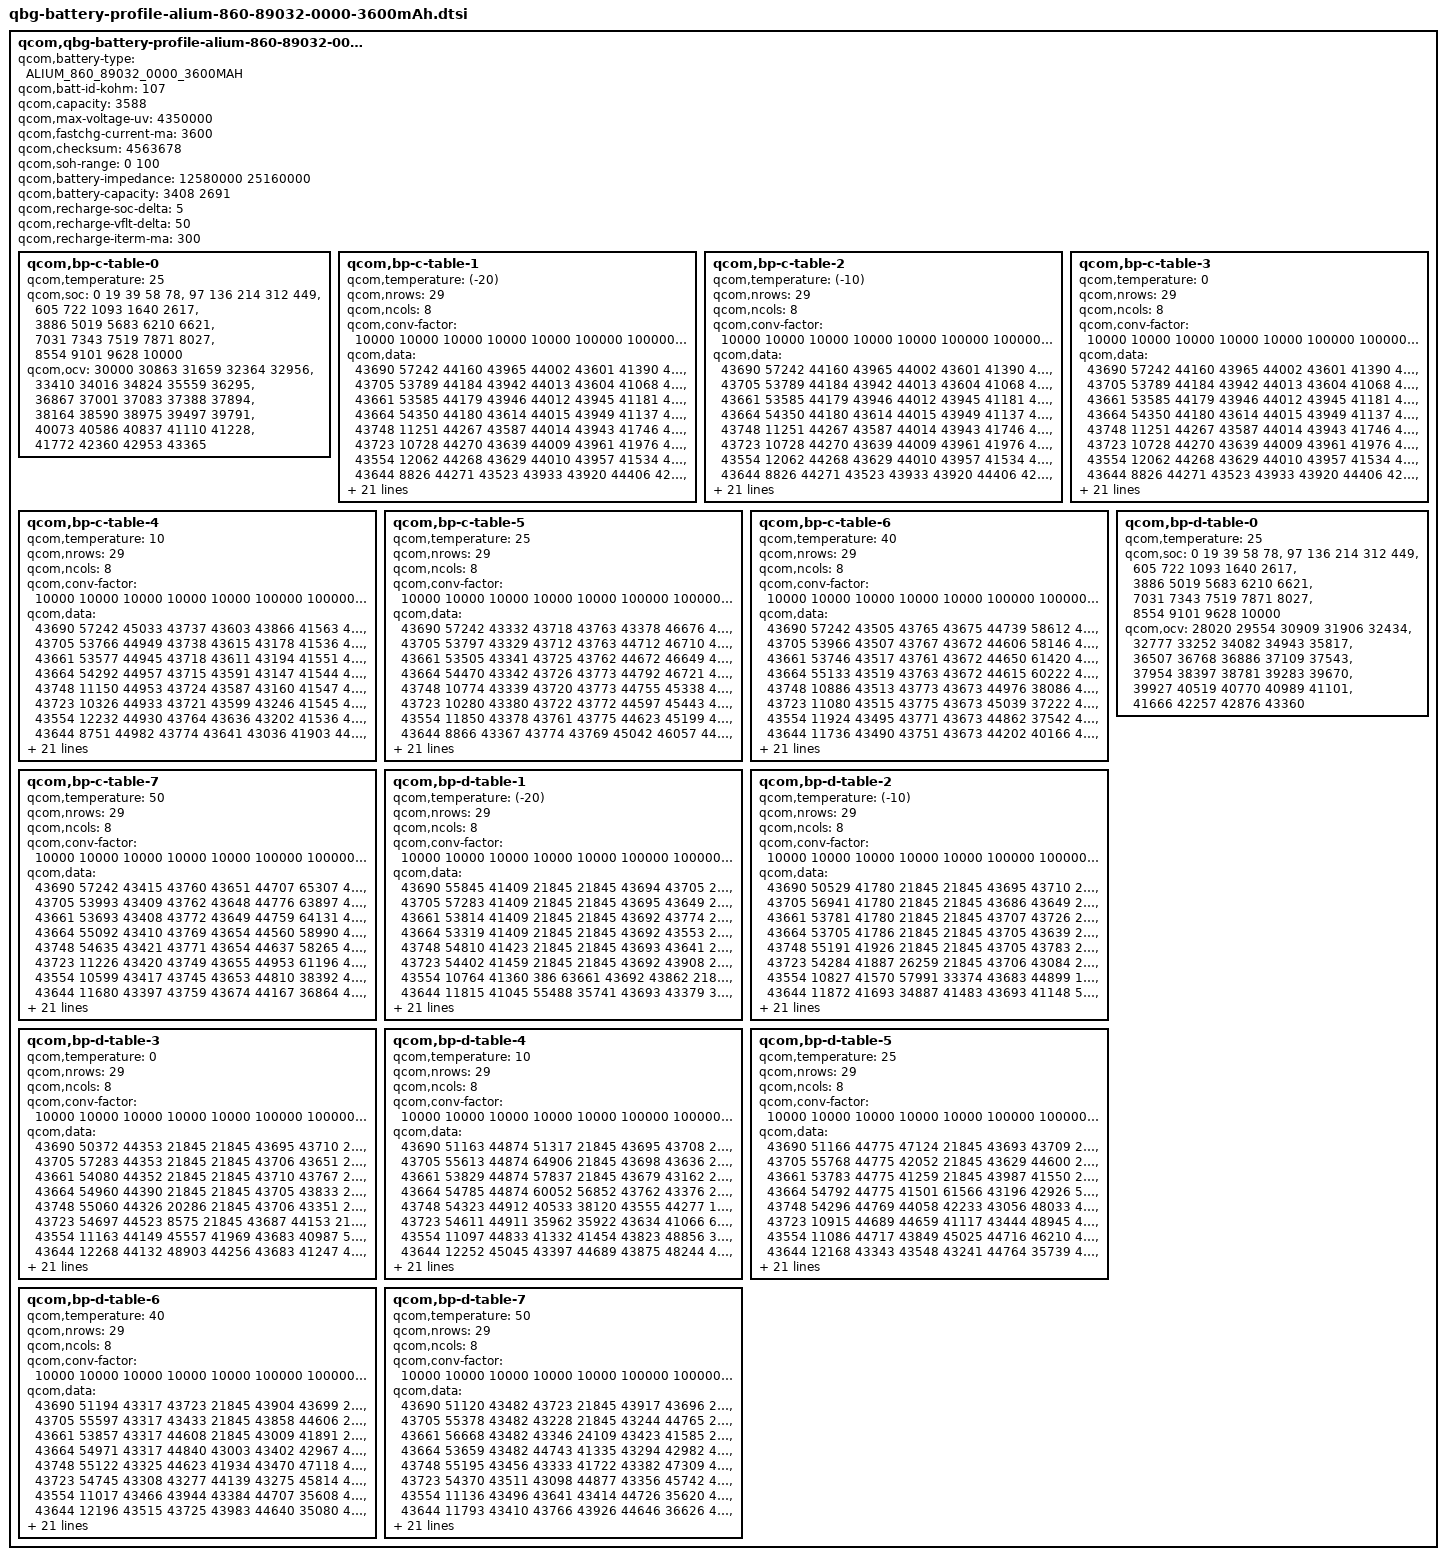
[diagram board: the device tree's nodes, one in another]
qcom,qbg-battery-profile-alium-860-89032-0000-3600mAh {
	qcom,battery-type = "ALIUM_860_89032_0000_3600MAH";
	qcom,batt-id-kohm = <107>;
	qcom,capacity = <3588>;
	qcom,max-voltage-uv = <4350000>;
	qcom,fastchg-current-ma = <3600>;
	qcom,checksum = <4563678>; /*@5, 0.005V, 10% */
	qcom,soh-range = <0 100>;
	qcom,battery-impedance = <12580000 25160000>; /* Nominal_Impedance in 10nohm @ SOC 50% 25C* 0:fresh cell, 1: aged cell */
	qcom,battery-capacity = <3408 2691>; /* Nominal_Capacity in mAh. 0: fresh cell, 1:aged cell */
	qcom,recharge-soc-delta =<5>; /* SOC delta (in percent) dropped from EOC SOC to enable recharge */
	qcom,recharge-vflt-delta =<50>; /* vfloat delta (in mV) dropped from regular vfloat in recharge */
	qcom,recharge-iterm-ma = <300>; /* termination current (in mA) in recharge */

	qcom,bp-c-table-0 {
		qcom,temperature = <25>;
		qcom,soc = <    0    19    39    58    78>,
			<   97   136   214   312   449>,
			<  605   722  1093  1640  2617>,
			< 3886  5019  5683  6210  6621>,
			< 7031  7343  7519  7871  8027>,
			< 8554  9101  9628 10000>;
		qcom,ocv = <30000 30863 31659 32364 32956>,
			<33410 34016 34824 35559 36295>,
			<36867 37001 37083 37388 37894>,
			<38164 38590 38975 39497 39791>,
			<40073 40586 40837 41110 41228>,
			<41772 42360 42953 43365>;
	};

	qcom,bp-c-table-1 {
		qcom,temperature = <(-20)>;
		qcom,nrows = <29>;
		qcom,ncols = <8>;
		qcom,conv-factor = <10000 10000 10000 10000 10000 100000 100000 10000>;
		qcom,data = <43690 57242 44160 43965 44002 43601 41390 42954>,
			<43705 53789 44184 43942 44013 43604 41068 42903>,
			<43661 53585 44179 43946 44012 43945 41181 42931>,
			<43664 54350 44180 43614 44015 43949 41137 42589>,
			<43748 11251 44267 43587 44014 43943 41746 42623>,
			<43723 10728 44270 43639 44009 43961 41976 42526>,
			<43554 12062 44268 43629 44010 43957 41534 42717>,
			<43644  8826 44271 43523 43933 43920 44406 42687>,
			<43922  8449 44185 43570 43907 43976 41611 41327>,
			<43883  9254 44179 43730 43919 43808 44367 41425>,
			<43255 14867 44167 43672 44001 44025 45053 41445>,
			<43128 15244 44168 43672 44029 44024 45048 41451>,
			<44783 15158 44173 43774 44013 43988 44048 41467>,
			<44226 14421 44161 43540 44013 43793 41113 41326>,
			<41107 15967 44173 43625 43776 43793 41789 41295>,
			<42372 15526 44884 43584 43856 43898 41322 41282>,
			<47409 15831 44867 43908 43900 43066 47981 41317>,
			<48281 12906 44874 44012 43875 43131 48704 41247>,
			<45800 13155 44916 43995 43899 43076 48598 41287>,
			<45943 12500 44865 43789 43856 43091 45767 42694>,
			<45533 12745 44884 43866 43224 43448 45801 42993>,
			<46597 13859 44193 43189 43133 43499 45732 42112>,
			<47093 14086 44221 43184 43128 43496 48592 42215>,
			<46101  2729 44165 43176 43029 43392 48814 42199>,
			<46577  2616 44188 43179 43085 43392 47122 42001>,
			<35776  2202 44260 43180 43334 43496 42250 42316>,
			<35111  3788 44259 43191 44671 43496 42897 48054>,
			<36662  3128 44267 43146 44800 43421 41436 47272>,
			<36282   748 44268 43594 44960 41594 44901 47858>;
	};

	qcom,bp-c-table-2 {
		qcom,temperature = <(-10)>;
		qcom,nrows = <29>;
		qcom,ncols = <8>;
		qcom,conv-factor = <10000 10000 10000 10000 10000 100000 100000 10000>;
		qcom,data = <43690 57242 44160 43965 44002 43601 41390 42954>,
			<43705 53789 44184 43942 44013 43604 41068 42903>,
			<43661 53585 44179 43946 44012 43945 41181 42931>,
			<43664 54350 44180 43614 44015 43949 41137 42589>,
			<43748 11251 44267 43587 44014 43943 41746 42623>,
			<43723 10728 44270 43639 44009 43961 41976 42526>,
			<43554 12062 44268 43629 44010 43957 41534 42717>,
			<43644  8826 44271 43523 43933 43920 44406 42687>,
			<43922  8449 44185 43570 43907 43976 41611 41327>,
			<43883  9254 44179 43730 43919 43808 44367 41425>,
			<43255 14867 44167 43672 44001 44025 45053 41445>,
			<43128 15244 44168 43672 44029 44024 45048 41451>,
			<44783 15158 44173 43774 44013 43988 44048 41467>,
			<44226 14421 44161 43540 44013 43793 41113 41326>,
			<41107 15967 44173 43625 43776 43793 41789 41295>,
			<42372 15526 44884 43584 43856 43898 41322 41282>,
			<47409 15831 44867 43908 43900 43066 47981 41317>,
			<48281 12906 44874 44012 43875 43131 48704 41247>,
			<45800 13155 44916 43995 43899 43076 48598 41287>,
			<45943 12500 44865 43789 43856 43091 45767 42694>,
			<45533 12745 44884 43866 43224 43448 45801 42993>,
			<46597 13859 44193 43189 43133 43499 45732 42112>,
			<47093 14086 44221 43184 43128 43496 48592 42215>,
			<46101  2729 44165 43176 43029 43392 48814 42199>,
			<46577  2616 44188 43179 43085 43392 47122 42001>,
			<35776  2202 44260 43180 43334 43496 42250 42316>,
			<35111  3788 44259 43191 44671 43496 42897 48054>,
			<36662  3128 44267 43146 44800 43421 41436 47272>,
			<36282   748 44268 43594 44960 41594 44901 47858>;
	};

	qcom,bp-c-table-3 {
		qcom,temperature = <0>;
		qcom,nrows = <29>;
		qcom,ncols = <8>;
		qcom,conv-factor = <10000 10000 10000 10000 10000 100000 100000 10000>;
		qcom,data = <43690 57242 44160 43965 44002 43601 41390 42954>,
			<43705 53789 44184 43942 44013 43604 41068 42903>,
			<43661 53585 44179 43946 44012 43945 41181 42931>,
			<43664 54350 44180 43614 44015 43949 41137 42589>,
			<43748 11251 44267 43587 44014 43943 41746 42623>,
			<43723 10728 44270 43639 44009 43961 41976 42526>,
			<43554 12062 44268 43629 44010 43957 41534 42717>,
			<43644  8826 44271 43523 43933 43920 44406 42687>,
			<43922  8449 44185 43570 43907 43976 41611 41327>,
			<43883  9254 44179 43730 43919 43808 44367 41425>,
			<43255 14867 44167 43672 44001 44025 45053 41445>,
			<43128 15244 44168 43672 44029 44024 45048 41451>,
			<44783 15158 44173 43774 44013 43988 44048 41467>,
			<44226 14421 44161 43540 44013 43793 41113 41326>,
			<41107 15967 44173 43625 43776 43793 41789 41295>,
			<42372 15526 44884 43584 43856 43898 41322 41282>,
			<47409 15831 44867 43908 43900 43066 47981 41317>,
			<48281 12906 44874 44012 43875 43131 48704 41247>,
			<45800 13155 44916 43995 43899 43076 48598 41287>,
			<45943 12500 44865 43789 43856 43091 45767 42694>,
			<45533 12745 44884 43866 43224 43448 45801 42993>,
			<46597 13859 44193 43189 43133 43499 45732 42112>,
			<47093 14086 44221 43184 43128 43496 48592 42215>,
			<46101  2729 44165 43176 43029 43392 48814 42199>,
			<46577  2616 44188 43179 43085 43392 47122 42001>,
			<35776  2202 44260 43180 43334 43496 42250 42316>,
			<35111  3788 44259 43191 44671 43496 42897 48054>,
			<36662  3128 44267 43146 44800 43421 41436 47272>,
			<36282   748 44268 43594 44960 41594 44901 47858>;
	};

	qcom,bp-c-table-4 {
		qcom,temperature = <10>;
		qcom,nrows = <29>;
		qcom,ncols = <8>;
		qcom,conv-factor = <10000 10000 10000 10000 10000 100000 100000 10000>;
		qcom,data = <43690 57242 45033 43737 43603 43866 41563 41506>,
			<43705 53766 44949 43738 43615 43178 41536 41690>,
			<43661 53577 44945 43718 43611 43194 41551 41715>,
			<43664 54292 44957 43715 43591 43147 41544 41705>,
			<43748 11150 44953 43724 43587 43160 41547 41607>,
			<43723 10326 44933 43721 43599 43246 41545 41661>,
			<43554 12232 44930 43764 43636 43202 41536 44378>,
			<43644  8751 44982 43774 43641 43036 41903 44295>,
			<43922  8649 44987 43750 43619 43445 41931 44506>,
			<43883  9454 44972 43751 43542 43300 41165 44527>,
			<43255 15062 44630 43675 43626 43382 41676 44476>,
			<43128 14925 44628 43679 43624 44718 41718 44452>,
			<44783 15341 44627 43769 43549 43379 41249 44470>,
			<44226 14371 44627 43637 43736 44651 37910 44528>,
			<41107 15906 44613 43608 43735 44644 60857 44534>,
			<42372 16330 44671 43960 43543 44544 57836 44350>,
			<47409 15371 44642 43907 43608 44553 57110 44399>,
			<48281 12899 44650 43963 43583 44742 57671 44522>,
			<45800 12525 44571 43615 43579 44729 36578 44455>,
			<45943 12714 44546 43958 43523 43379 36745 44437>,
			<45533 13989 44546 44029 43592 43367 33164 44314>,
			<46597 14183 44546 44013 43587 43369 36861 44292>,
			<47093 13706 44550 43911 43595 43295 45396 44349>,
			<46101  2616 44574 44008 43586 43268 45463 44309>,
			<46577  2653 44562 44016 43607 43290 46905 44379>,
			<35776  2120 44573 44021 44000 43285 45839 41703>,
			<35111  4019 44651 44023 43872 43336 48949 41545>,
			<36662  3523 44564 43604 43218 44073 42138 41879>,
			<36282   937 44666 43576 43065 43488 41623 41555>;
	};

	qcom,bp-c-table-5 {
		qcom,temperature = <25>;
		qcom,nrows = <29>;
		qcom,ncols = <8>;
		qcom,conv-factor = <10000 10000 10000 10000 10000 100000 100000 10000>;
		qcom,data = <43690 57242 43332 43718 43763 43378 46676 44985>,
			<43705 53797 43329 43712 43763 44712 46710 44963>,
			<43661 53505 43341 43725 43762 44672 46649 44629>,
			<43664 54470 43342 43726 43773 44792 46721 44636>,
			<43748 10774 43339 43720 43773 44755 45338 44614>,
			<43723 10280 43380 43722 43772 44597 45443 44617>,
			<43554 11850 43378 43761 43775 44623 45199 44665>,
			<43644  8866 43367 43774 43769 45042 46057 44573>,
			<43922  8269 43368 43770 43770 44818 46020 44554>,
			<43883 10093 43283 43769 43746 44874 46300 44581>,
			<43255 15017 43289 43749 43755 44267 35516 44753>,
			<43128 14883 43288 43668 43748 44088 48866 44766>,
			<44783 14961 43291 43763 43757 44915 36601 44589>,
			<44226 14502 43268 43733 43770 44193 64491 44571>,
			<41107 16044 43276 43565 43766 44884 63795 44561>,
			<42372 16318 43312 43571 43720 44857 63606 44643>,
			<47409 15380 43301 43577 43582 45042 33472 44609>,
			<48281 12949 43298 43570 43545 44804 61244 44962>,
			<45800 12515 43307 43558 43724 44812 58642 44599>,
			<45943 12741 43472 43562 43722 44959 35952 44579>,
			<45533 13859 43474 43533 43735 45034 39071 44647>,
			<46597 13344 43472 43561 43728 44966 35574 44546>,
			<47093 13615 43478 43743 43741 44634 45953 44594>,
			<46101  2620 43473 43576 43740 44978 35216 44575>,
			<46577  2982 43473 43568 43740 44935 35895 44567>,
			<35776  2438 43475 43531 43560 44929 36356 44645>,
			<35111  4050 43474 43532 43547 44954 35561 44975>,
			<36662  3427 43473 43582 43603 45036 45867 44945>,
			<36282   975 43472 43723 43960 44931 42369 44980>;
	};

	qcom,bp-c-table-6 {
		qcom,temperature = <40>;
		qcom,nrows = <29>;
		qcom,ncols = <8>;
		qcom,conv-factor = <10000 10000 10000 10000 10000 100000 100000 10000>;
		qcom,data = <43690 57242 43505 43765 43675 44739 58612 44734>,
			<43705 53966 43507 43767 43672 44606 58146 44709>,
			<43661 53746 43517 43761 43672 44650 61420 44704>,
			<43664 55133 43519 43763 43672 44615 60222 44716>,
			<43748 10886 43513 43773 43673 44976 38086 44715>,
			<43723 11080 43515 43775 43673 45039 37222 43351>,
			<43554 11924 43495 43771 43673 44862 37542 43358>,
			<43644 11736 43490 43751 43673 44202 40166 43341>,
			<43922  8444 43497 43744 43674 44258 38461 43382>,
			<43883 10129 43413 43756 43674 44094 38631 43384>,
			<43255  9512 43414 43755 43648 44120 60617 43368>,
			<43128 14976 43409 43666 43662 44472 40898 43289>,
			<44783 15069 43408 43758 43678 44051 60003 43364>,
			<44226 15113 43411 43750 43750 44093 59439 43332>,
			<41107 14650 43420 43774 43770 44224 65165 43346>,
			<42372 15936 43397 43763 43748 44800 38880 43357>,
			<47409 15366 43394 43713 43721 44903 39733 44726>,
			<48281 12945 43406 43721 43557 44205 40872 44688>,
			<45800 12433 43402 43761 43714 44270 60945 44713>,
			<45943 12572 43446 43774 43753 44908 40456 43385>,
			<45533 13949 43440 43727 43723 44854 40753 44715>,
			<46597 13367 43440 43749 43771 44922 35253 43377>,
			<47093 13773 43441 43748 43750 44923 34973 43389>,
			<46101  2603 43440 43764 43769 44811 34575 43334>,
			<46577  2981 43443 43722 43775 44852 33813 43354>,
			<35776  2543 43452 43720 43767 44850 33075 43346>,
			<35111  3848 43455 43715 43730 44802 33637 44721>,
			<36662  3422 43454 43765 43530 44914 34945 44700>,
			<36282   808 43449 43712 43765 44073 36789 43345>;
	};

	qcom,bp-c-table-7 {
		qcom,temperature = <50>;
		qcom,nrows = <29>;
		qcom,ncols = <8>;
		qcom,conv-factor = <10000 10000 10000 10000 10000 100000 100000 10000>;
		qcom,data = <43690 57242 43415 43760 43651 44707 65307 43336>,
			<43705 53993 43409 43762 43648 44776 63897 43381>,
			<43661 53693 43408 43772 43649 44759 64131 43377>,
			<43664 55092 43410 43769 43654 44560 58990 43378>,
			<43748 54635 43421 43771 43654 44637 58265 43390>,
			<43723 11226 43420 43749 43655 44953 61196 43387>,
			<43554 10599 43417 43745 43653 44810 38392 43361>,
			<43644 11680 43397 43759 43674 44167 36864 43370>,
			<43922  9049 43398 43755 43674 44072 38762 43293>,
			<43883  9841 43395 43668 43652 44132 60565 43268>,
			<43255  9603 43405 43666 43651 44505 64189 43317>,
			<43128  9539 43404 43654 43701 44304 38320 43299>,
			<44783 14995 43404 43676 43678 44532 37230 43267>,
			<44226 15345 43404 43671 43745 44471 59557 43373>,
			<41107 14817 43401 43754 43749 44115 57646 43366>,
			<42372 15972 43447 43745 43759 44219 61314 43360>,
			<47409 15366 43452 43774 43764 44823 32791 43328>,
			<48281 13038 43451 43772 43733 44214 39831 44718>,
			<45800 12516 43428 43756 43760 44284 37974 43367>,
			<45943 12665 43425 43759 43668 44209 38319 43270>,
			<45533 14270 43427 43748 43769 44874 38717 43360>,
			<46597 13355 43427 43744 43753 44871 37475 43294>,
			<47093 13725 43427 43745 43755 44864 36926 43294>,
			<46101  2768 43437 43770 43744 44870 36983 43370>,
			<46577  2994 43436 43770 43750 44874 37629 43368>,
			<35776  2559 43438 43774 43775 44905 40470 43364>,
			<35111  3858 43435 43773 43739 44822 33978 43329>,
			<36662   687 43093 43748 43582 44877 36384 44712>,
			<36282   813 43088 43768 43723 44316 35572 43367>;
	};

	qcom,bp-d-table-0 {
		qcom,temperature = <25>;
		qcom,soc = <    0    19    39    58    78>,
			<   97   136   214   312   449>,
			<  605   722  1093  1640  2617>,
			< 3886  5019  5683  6210  6621>,
			< 7031  7343  7519  7871  8027>,
			< 8554  9101  9628 10000>;
		qcom,ocv = <28020 29554 30909 31906 32434>,
			<32777 33252 34082 34943 35817>,
			<36507 36768 36886 37109 37543>,
			<37954 38397 38781 39283 39670>,
			<39927 40519 40770 40989 41101>,
			<41666 42257 42876 43360>;
	};

	qcom,bp-d-table-1 {
		qcom,temperature = <(-20)>;
		qcom,nrows = <29>;
		qcom,ncols = <8>;
		qcom,conv-factor = <10000 10000 10000 10000 10000 100000 100000 10000>;
		qcom,data = <43690 55845 41409 21845 21845 43694 43705 21845>,
			<43705 57283 41409 21845 21845 43695 43649 21845>,
			<43661 53814 41409 21845 21845 43692 43774 21845>,
			<43664 53319 41409 21845 21845 43692 43553 21845>,
			<43748 54810 41423 21845 21845 43693 43641 21845>,
			<43723 54402 41459 21845 21845 43692 43908 21845>,
			<43554 10764 41360   386 63661 43692 43862 21845>,
			<43644 11815 41045 55488 35741 43693 43379 30577>,
			<43922 11521 40982 63723 47555 43692 44886  2459>,
			<43883  8395 40961 40248 41338 43693 41911 56339>,
			<43255  9955 41091 36084 44402 43682 42515 62276>,
			<43128 10223 41131 35399 44101 43683 42773 64460>,
			<44783  9704 41823 46673 41699 43683 42089 59385>,
			<44226 14850 41143 48413 44295 43683 41448 60636>,
			<41107 14470 41122 47597 44870 43683 41937 38251>,
			<42372 14606 41812 42195 44615 43680 41542 37878>,
			<47409 15985 41854 41448 44604 43680 41607 40513>,
			<48281 16148 41794 41828 44585 43681 41726 38979>,
			<45800 15381 41806 41905 44594 43686 41969 39793>,
			<45943 15731 41798 41478 44633 43686 41207 39887>,
			<45533 13236 41801 41648 44856 43687 41125 39843>,
			<46597 12457 41803 44366 44825 43684 41587 39528>,
			<47093 12368 41847 44357 44282 43684 41945 39914>,
			<46101 13694 41835 41903 42479 43707 48631 37286>,
			<46577  2623 41749 41916 47842 43707 45706 38580>,
			<35776  2973 41829 41705 42094 43684 44421 36912>,
			<35111  2462 41744 42345 41789 43705 41209 38706>,
			<36662  3291 41803 47453 41798 43680 44262 61324>,
			<36282   824 41130 49041 41026 43690 43690 57741>;
	};

	qcom,bp-d-table-2 {
		qcom,temperature = <(-10)>;
		qcom,nrows = <29>;
		qcom,ncols = <8>;
		qcom,conv-factor = <10000 10000 10000 10000 10000 100000 100000 10000>;
		qcom,data = <43690 50529 41780 21845 21845 43695 43710 21845>,
			<43705 56941 41780 21845 21845 43686 43649 21845>,
			<43661 53781 41780 21845 21845 43707 43726 21845>,
			<43664 53705 41786 21845 21845 43705 43639 21845>,
			<43748 55191 41926 21845 21845 43705 43783 21845>,
			<43723 54284 41887 26259 21845 43706 43084 21845>,
			<43554 10827 41570 57991 33374 43683 44899 13506>,
			<43644 11872 41693 34887 41483 43693 41148 58785>,
			<43922  8945 41723 45501 44208 43683 42555 59581>,
			<43883  8511 41617 48394 44812 43683 42113 38905>,
			<43255 10081 41616 48662 45012 43683 47757 37739>,
			<43128  9325 41620 47175 45045 43683 47861 40400>,
			<44783 14980 41610 47875 44222 43680 42894 40088>,
			<44226 15283 41655 42088 44658 43680 41019 39731>,
			<41107 14547 41612 40973 43366 43681 41203 33074>,
			<42372 14666 41636 44169 43504 43685 41934 36413>,
			<47409 15952 41614 44693 43437 43711 41572 35331>,
			<48281 15535 41661 43367 43452 43703 40975 46479>,
			<45800 15822 41647 43281 43387 43661 42933 46164>,
			<45943 12863 41660 43314 44773 43673 42509 46146>,
			<45533 13183 41609 43470 44759 43714 41320 46141>,
			<46597 12703 41656 44685 44644 43848 46238 46364>,
			<47093 14042 41634 44693 44831 43198 35723 35713>,
			<46101  2988 44380 43499 47654 43534 47325 32959>,
			<46577  3026 44383 43403 47882 43724 42882 32895>,
			<35776  2975 41639 43307 41368 43771 44987 36726>,
			<35111  3791 41637 41594 44489 43612 47500 33289>,
			<36662  3194 44373 44431 44116 43624 43080 33297>,
			<36282   806 44381 43232 41661 43649 43690 33325>;
	};

	qcom,bp-d-table-3 {
		qcom,temperature = <0>;
		qcom,nrows = <29>;
		qcom,ncols = <8>;
		qcom,conv-factor = <10000 10000 10000 10000 10000 100000 100000 10000>;
		qcom,data = <43690 50372 44353 21845 21845 43695 43710 21845>,
			<43705 57283 44353 21845 21845 43706 43651 21845>,
			<43661 54080 44352 21845 21845 43710 43767 21845>,
			<43664 54960 44390 21845 21845 43705 43833 21845>,
			<43748 55060 44326 20286 21845 43706 43351 21845>,
			<43723 54697 44523  8575 21845 43687 44153 21845>,
			<43554 11163 44149 45557 41969 43683 40987 59942>,
			<43644 12268 44132 48903 44256 43683 41247 40065>,
			<43922  8812 44055 47152 44840 43683 42691 39684>,
			<43883  9907 44055 42216 44970 43680 42793 33116>,
			<43255  9257 44086 41051 44639 43686 42381 36297>,
			<43128  9715 44088 41774 44651 43687 42165 36436>,
			<44783 14980 44069 41632 44713 43685 41084 34994>,
			<44226 15283 44072 44620 43468 43699 41436 45364>,
			<41107 14462 44078 43247 43096 43761 41254 48684>,
			<42372 14663 44241 44008 43855 43946 41385 47752>,
			<47409 16281 44235 43946 43899 43992 41413 41992>,
			<48281 15459 44275 43985 43177 43085 48564 42109>,
			<45800 13044 44278 43898 43217 43307 45390 42432>,
			<45943 13097 44233 43841 43056 43487 45412 42281>,
			<45533 12396 44287 43863 43054 43412 47092 42489>,
			<46597 13455 44268 43144 41636 43507 46025 48762>,
			<47093 13798 44267 43246 41974 43510 48267 48266>,
			<46101 13662 44267 43124 44571 43041 42674 47342>,
			<46577  2789 44264 43076 43384 43200 41381 48070>,
			<35776  2249 44256 43229 43274 43134 47578 48041>,
			<35111  3588 44256 43228 43437 43013 47562 47678>,
			<36662  3472 44265 43198 43011 43114 47227 47750>,
			<36282   980 44181 43897 43040 43100 47147 42319>;
	};

	qcom,bp-d-table-4 {
		qcom,temperature = <10>;
		qcom,nrows = <29>;
		qcom,ncols = <8>;
		qcom,conv-factor = <10000 10000 10000 10000 10000 100000 100000 10000>;
		qcom,data = <43690 51163 44874 51317 21845 43695 43708 21845>,
			<43705 55613 44874 64906 21845 43698 43636 21845>,
			<43661 53829 44874 57837 21845 43679 43162 21845>,
			<43664 54785 44874 60052 56852 43762 43376 29256>,
			<43748 54323 44912 40533 38120 43555 44277 11699>,
			<43723 54611 44911 35962 35922 43634 41066 62404>,
			<43554 11097 44833 41332 41454 43823 48856 35640>,
			<43644 12252 45045 43397 44689 43875 48244 47349>,
			<43922  8820 45050 43053 43496 43850 48900 42268>,
			<43883  9961 45035 43182 43056 43167 48201 42964>,
			<43255  9333 44954 43886 43063 43045 48146 42504>,
			<43128  9578 44955 43805 43041 43011 48180 42750>,
			<44783 14999 44936 44013 43879 43149 47866 41069>,
			<44226 15256 44939 43960 43990 43433 48721 41832>,
			<41107 14462 44986 43549 43913 43510 47298 41530>,
			<42372 16045 44973 43540 43590 44761 45578 41651>,
			<47409 16231 44639 43630 43606 44546 48572 44353>,
			<48281 15843 44638 43643 43966 44595 45772 44379>,
			<45800 12823 44608 43607 44029 44757 46718 41724>,
			<45943 13124 44608 43958 43795 44746 46866 41596>,
			<45533 12766 44623 43926 43210 44698 46792 41787>,
			<46597 13469 44656 43800 43394 43368 47963 41080>,
			<47093 13805 44669 43879 43500 43321 42473 41376>,
			<46101  2737 44662 43970 43868 43458 47973 41931>,
			<46577  2594 44663 44024 43779 43471 47119 41903>,
			<35776  2079 44656 44013 43987 43460 47382 41598>,
			<35111  3666 44618 43936 44031 43298 47241 41518>,
			<36662  3521 44662 43605 44015 43385 48696 41682>,
			<36282   990 44665 43913 44000 44710 45581 41527>;
	};

	qcom,bp-d-table-5 {
		qcom,temperature = <25>;
		qcom,nrows = <29>;
		qcom,ncols = <8>;
		qcom,conv-factor = <10000 10000 10000 10000 10000 100000 100000 10000>;
		qcom,data = <43690 51166 44775 47124 21845 43693 43709 21845>,
			<43705 55768 44775 42052 21845 43629 44600 21845>,
			<43661 53783 44775 41259 21845 43987 41550 21845>,
			<43664 54792 44775 41501 61566 43196 42926 50758>,
			<43748 54296 44769 44058 42233 43056 48033 45433>,
			<43723 10915 44689 44659 41117 43444 48945 48852>,
			<43554 11086 44717 43849 45025 44716 46210 41271>,
			<43644 12168 43343 43548 43241 44764 35739 44523>,
			<43922  8917 43382 43569 44012 44547 35662 44210>,
			<43883  8515 43365 43554 43593 44988 35035 44838>,
			<43255  9265 43372 43741 43644 45034 46786 45047>,
			<43128  9482 43374 43566 43602 45013 46325 44832>,
			<44783 15036 43371 43767 43558 45011 48146 44634>,
			<44226 14943 43287 43774 43732 44830 48165 44644>,
			<41107 14349 43282 43772 43738 44804 45963 44562>,
			<42372 16104 43271 43737 43582 44926 36856 44609>,
			<47409 16215 43316 43774 43564 44894 48867 44547>,
			<48281 15831 43325 43762 43580 44861 48983 44569>,
			<45800 13273 43320 43572 43912 45050 47025 44833>,
			<45943 12380 43322 43549 43835 44981 45972 44217>,
			<45533 12637 43303 43534 43950 44554 48740 45022>,
			<46597 13549 43308 43538 43604 44773 48921 45008>,
			<47093 13800 43311 43542 43602 44779 49021 45008>,
			<46101  2743 43311 43552 43628 44746 47348 44985>,
			<46577  2599 43311 43733 43551 44739 47972 44638>,
			<35776  2152 43310 43730 43575 44582 48877 44666>,
			<35111  4027 43310 43772 43529 44971 42101 44568>,
			<36662  3542 43308 43769 43568 45054 42333 44546>,
			<36282   970 43309 43761 43553 45012 47510 44568>;
	};

	qcom,bp-d-table-6 {
		qcom,temperature = <40>;
		qcom,nrows = <29>;
		qcom,ncols = <8>;
		qcom,conv-factor = <10000 10000 10000 10000 10000 100000 100000 10000>;
		qcom,data = <43690 51194 43317 43723 21845 43904 43699 21845>,
			<43705 55597 43317 43433 21845 43858 44606 21845>,
			<43661 53857 43317 44608 21845 43009 41891 21845>,
			<43664 54971 43317 44840 43003 43402 42967 48409>,
			<43748 55122 43325 44623 41934 43470 47118 48114>,
			<43723 54745 43308 43277 44139 43275 45814 42567>,
			<43554 11017 43466 43944 43384 44707 35608 41661>,
			<43644 12196 43515 43725 43983 44640 35080 45034>,
			<43922  8933 43495 43764 43549 45017 35968 44591>,
			<43883  8451 43501 43750 43562 44206 35810 44702>,
			<43255  9457 43502 43745 43576 44228 46407 44779>,
			<43128  9716 43497 43768 43647 44266 46648 44576>,
			<44783  9572 43496 43753 43773 44229 36065 43345>,
			<44226 14901 43498 43752 43775 44067 33852 43359>,
			<41107 14564 43415 43754 43746 44071 39629 43337>,
			<42372 16023 43423 43754 43735 44087 35414 44730>,
			<47409 15530 43393 43752 43762 44272 35657 43337>,
			<48281 15656 43404 43747 43764 44882 35074 43334>,
			<45800 13269 43400 43721 43618 44855 46400 44762>,
			<45943 12730 43402 43717 43614 44840 45218 44545>,
			<45533 14004 43445 43764 43573 44629 45722 44777>,
			<46597 13474 43446 43725 43533 44665 45641 44793>,
			<47093 13389 43441 43715 43522 44645 45991 44796>,
			<46101 13640 43443 43768 43735 44980 48200 44709>,
			<46577  2762 43442 43750 43738 44948 48336 43345>,
			<35776  2098 43452 43750 43722 44838 45237 43340>,
			<35111  3676 43454 43746 43760 44803 45373 43379>,
			<36662  3569 43454 43747 43774 44828 46449 43384>,
			<36282   900 43454 43744 43768 44830 35264 43385>;
	};

	qcom,bp-d-table-7 {
		qcom,temperature = <50>;
		qcom,nrows = <29>;
		qcom,ncols = <8>;
		qcom,conv-factor = <10000 10000 10000 10000 10000 100000 100000 10000>;
		qcom,data = <43690 51120 43482 43723 21845 43917 43696 21845>,
			<43705 55378 43482 43228 21845 43244 44765 21845>,
			<43661 56668 43482 43346 24109 43423 41585 21159>,
			<43664 53659 43482 44743 41335 43294 42982 48852>,
			<43748 55195 43456 43333 41722 43382 47309 42416>,
			<43723 54370 43511 43098 44877 43356 45742 41469>,
			<43554 11136 43496 43641 43414 44726 35620 44432>,
			<43644 11793 43410 43766 43926 44646 36626 44613>,
			<43922 11605 43423 43775 43532 44855 33761 44773>,
			<43883  8703 43419 43758 43743 44170 35271 44717>,
			<43255  9378 43396 43668 43561 44090 46107 44705>,
			<43128  9610 43399 43747 43635 44034 46844 44742>,
			<44783  9529 43399 43666 43775 44116 36331 43385>,
			<44226 15093 43393 43676 43762 44430 39369 43384>,
			<41107 14501 43395 43674 43745 44433 39567 43287>,
			<42372 16024 43403 43672 43743 44489 46412 43337>,
			<47409 16209 43442 43676 43770 44142 36065 43282>,
			<48281 15829 43448 43667 43774 44283 36585 43286>,
			<45800 13278 43431 43744 43535 44800 46795 44727>,
			<45943 12724 43425 43774 43631 44998 45964 44768>,
			<45533 14071 43424 43748 43565 44993 45928 44718>,
			<46597 14205 43426 43768 43552 44982 45526 44707>,
			<47093 13363 43436 43768 43552 44961 45429 44707>,
			<46101 13675 43438 43752 43724 45001 45164 43384>,
			<46577  2810 43438 43754 43767 45009 45137 43374>,
			<35776  2093 43432 43755 43771 44814 35455 43292>,
			<35111  3651 43435 43752 43745 44851 36039 43269>,
			<36662  3552 43093 43667 43751 44276 35743 43279>,
			<36282   954 43092 43674 43771 44148 48769 43318>;
	};
};
